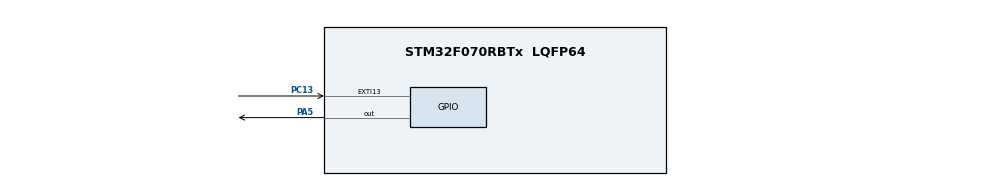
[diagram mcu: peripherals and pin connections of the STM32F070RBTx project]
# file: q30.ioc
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Mcu.Family=STM32F0
Mcu.Name=STM32F070RBTx
Mcu.Package=LQFP64
NVIC.EXTI4_15_IRQn=true\:0\:0\:false\:false\:true\:true\:true\:true
NVIC.TIM16_IRQn=true\:0\:0\:false\:false\:true\:true\:true\:true
PA5.Signal=GPIO_Output
PC13.Signal=GPXTI13
ProjectManager.HeapSize=0x200
ProjectManager.StackSize=0x400
ProjectManager.TargetToolchain=MDK-ARM V5.32
TIM16.Period=1000-1
TIM16.Prescaler=8000-1
VP_TIM16_VS_ClockSourceINT.Mode=Enable_Timer
board=custom

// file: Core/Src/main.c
/* USER CODE BEGIN Header */
/**
  ******************************************************************************
  * @file           : main.c
  * @brief          : Main program body
  ******************************************************************************
  * @attention
  *
  * Copyright (c) 2023 STMicroelectronics.
  * All rights reserved.
  *
  * This software is licensed under terms that can be found in the LICENSE file
  * in the root directory of this software component.
  * If no LICENSE file comes with this software, it is provided AS-IS.
  *
  ******************************************************************************
  */
/* USER CODE END Header */
#include "main.h"

TIM_HandleTypeDef htim16;

/* USER CODE BEGIN PV */
int flag = 0;
/* USER CODE END PV */

void SystemClock_Config(void);
static void MX_GPIO_Init(void);
static void MX_TIM16_Init(void);

/* USER CODE BEGIN 0 */
void HAL_GPIO_EXTI_Callback(uint16_t GPIO_Pin)
{
	if (GPIO_Pin==GPIO_PIN_13){
		flag ^= 1;
	}

}
void HAL_TIM_PeriodElapsedCallback(TIM_HandleTypeDef *htim)
{
	HAL_GPIO_TogglePin(GPIOA,GPIO_PIN_5);
}
/* USER CODE END 0 */

int main(void)
{

  /* MCU Configuration--------------------------------------------------------*/

  /* Reset of all peripherals, Initializes the Flash interface and the Systick. */
  HAL_Init();

  /* Configure the system clock */
  SystemClock_Config();

  /* Initialize all configured peripherals */
  MX_GPIO_Init();
  MX_TIM16_Init();
  /* USER CODE BEGIN 2 */
	HAL_TIM_Base_Start_IT(&htim16);
  /* USER CODE END 2 */

  /* Infinite loop */
  while (1)
  {

    /* USER CODE BEGIN 3 */
		if(flag == 1)
		{
			HAL_TIM_Base_Start_IT(&htim16);
		}
		else
		{
			HAL_GPIO_WritePin(GPIOA,GPIO_PIN_5,GPIO_PIN_RESET);
			HAL_TIM_Base_Stop_IT(&htim16);
		}
  }
  /* USER CODE END 3 */
}

void SystemClock_Config(void)
{
  RCC_OscInitTypeDef RCC_OscInitStruct = {0};
  RCC_ClkInitTypeDef RCC_ClkInitStruct = {0};

  /** Initializes the RCC Oscillators according to the specified parameters
  * in the RCC_OscInitTypeDef structure.
  */
  RCC_OscInitStruct.OscillatorType = RCC_OSCILLATORTYPE_HSI;
  RCC_OscInitStruct.HSIState = RCC_HSI_ON;
  RCC_OscInitStruct.HSICalibrationValue = RCC_HSICALIBRATION_DEFAULT;
  RCC_OscInitStruct.PLL.PLLState = RCC_PLL_NONE;
  if (HAL_RCC_OscConfig(&RCC_OscInitStruct) != HAL_OK)
  {
    Error_Handler();
  }

  /** Initializes the CPU, AHB and APB buses clocks
  */
  RCC_ClkInitStruct.ClockType = RCC_CLOCKTYPE_HCLK|RCC_CLOCKTYPE_SYSCLK
                              |RCC_CLOCKTYPE_PCLK1;
  RCC_ClkInitStruct.SYSCLKSource = RCC_SYSCLKSOURCE_HSI;
  RCC_ClkInitStruct.AHBCLKDivider = RCC_SYSCLK_DIV1;
  RCC_ClkInitStruct.APB1CLKDivider = RCC_HCLK_DIV1;

  if (HAL_RCC_ClockConfig(&RCC_ClkInitStruct, FLASH_LATENCY_0) != HAL_OK)
  {
    Error_Handler();
  }
}

static void MX_TIM16_Init(void)
{

  htim16.Instance = TIM16;
  htim16.Init.Prescaler = 8000-1;
  htim16.Init.CounterMode = TIM_COUNTERMODE_UP;
  htim16.Init.Period = 1000-1;
  htim16.Init.ClockDivision = TIM_CLOCKDIVISION_DIV1;
  htim16.Init.RepetitionCounter = 0;
  htim16.Init.AutoReloadPreload = TIM_AUTORELOAD_PRELOAD_DISABLE;
  if (HAL_TIM_Base_Init(&htim16) != HAL_OK)
  {
    Error_Handler();
  }

}

static void MX_GPIO_Init(void)
{
  GPIO_InitTypeDef GPIO_InitStruct = {0};

  /* GPIO Ports Clock Enable */
  __HAL_RCC_GPIOC_CLK_ENABLE();
  __HAL_RCC_GPIOA_CLK_ENABLE();

  /*Configure GPIO pin Output Level */
  HAL_GPIO_WritePin(GPIOA, GPIO_PIN_5, GPIO_PIN_RESET);

  /*Configure GPIO pin : PC13 */
  GPIO_InitStruct.Pin = GPIO_PIN_13;
  GPIO_InitStruct.Mode = GPIO_MODE_IT_RISING;
  GPIO_InitStruct.Pull = GPIO_NOPULL;
  HAL_GPIO_Init(GPIOC, &GPIO_InitStruct);

  /*Configure GPIO pin : PA5 */
  GPIO_InitStruct.Pin = GPIO_PIN_5;
  GPIO_InitStruct.Mode = GPIO_MODE_OUTPUT_PP;
  GPIO_InitStruct.Pull = GPIO_NOPULL;
  GPIO_InitStruct.Speed = GPIO_SPEED_FREQ_LOW;
  HAL_GPIO_Init(GPIOA, &GPIO_InitStruct);

  /* EXTI interrupt init*/
  HAL_NVIC_SetPriority(EXTI4_15_IRQn, 0, 0);
  HAL_NVIC_EnableIRQ(EXTI4_15_IRQn);

}

void Error_Handler(void)
{
  __disable_irq();
  while (1)
  {
  }
}
